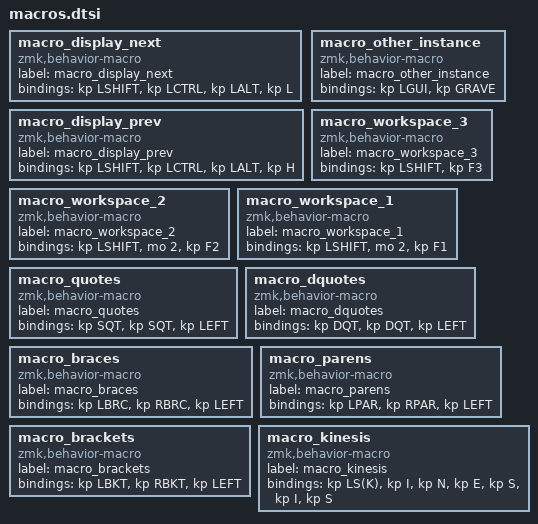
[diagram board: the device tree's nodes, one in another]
macro_display_next: macro_display_next{
compatible = "zmk,behavior-macro";
label = "macro_display_next";
#binding-cells = <0>;
bindings = <&kp LSHIFT>, <&kp LCTRL>, <&kp LALT>, <&kp L>;
};
macro_display_prev: macro_display_prev{
compatible = "zmk,behavior-macro";
label = "macro_display_prev";
#binding-cells = <0>;
bindings = <&kp LSHIFT>, <&kp LCTRL>, <&kp LALT>, <&kp H>;
};
macro_other_instance: macro_other_instance{
compatible = "zmk,behavior-macro";
label = "macro_other_instance";
#binding-cells = <0>;
bindings = <&kp LGUI>, <&kp GRAVE>;
};
macro_workspace_3: macro_workspace_3{
compatible = "zmk,behavior-macro";
label = "macro_workspace_3";
#binding-cells = <0>;
bindings = <&kp LSHIFT>, <&kp F3>;
};
macro_workspace_2: macro_workspace_2{
compatible = "zmk,behavior-macro";
label = "macro_workspace_2";
#binding-cells = <0>;
bindings = <&kp LSHIFT>, <&mo 2>, <&kp F2>;
};
macro_workspace_1: macro_workspace_1{
compatible = "zmk,behavior-macro";
label = "macro_workspace_1";
#binding-cells = <0>;
bindings = <&kp LSHIFT>, <&mo 2>, <&kp F1>;
};
macro_quotes: macro_quotes{
compatible = "zmk,behavior-macro";
label = "macro_quotes";
#binding-cells = <0>;
bindings = <&kp SQT>, <&kp SQT>, <&kp LEFT>;
};
macro_dquotes: macro_dquotes{
compatible = "zmk,behavior-macro";
label = "macro_dquotes";
#binding-cells = <0>;
bindings = <&kp DQT>, <&kp DQT>, <&kp LEFT>;
};
macro_braces: macro_braces{
compatible = "zmk,behavior-macro";
label = "macro_braces";
#binding-cells = <0>;
bindings = <&kp LBRC>, <&kp RBRC>, <&kp LEFT>;
};
macro_parens: macro_parens{
compatible = "zmk,behavior-macro";
label = "macro_parens";
#binding-cells = <0>;
bindings = <&kp LPAR>, <&kp RPAR>, <&kp LEFT>;
};
macro_brackets: macro_brackets{
compatible = "zmk,behavior-macro";
label = "macro_brackets";
#binding-cells = <0>;
bindings = <&kp LBKT>, <&kp RBKT>, <&kp LEFT>;
};
macro_kinesis: macro_kinesis{
compatible = "zmk,behavior-macro";
label = "macro_kinesis";
#binding-cells = <0>;
bindings = <&kp LS(K)>, <&kp I>, <&kp N>, <&kp E>, <&kp S>, <&kp I>, <&kp S>;
};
